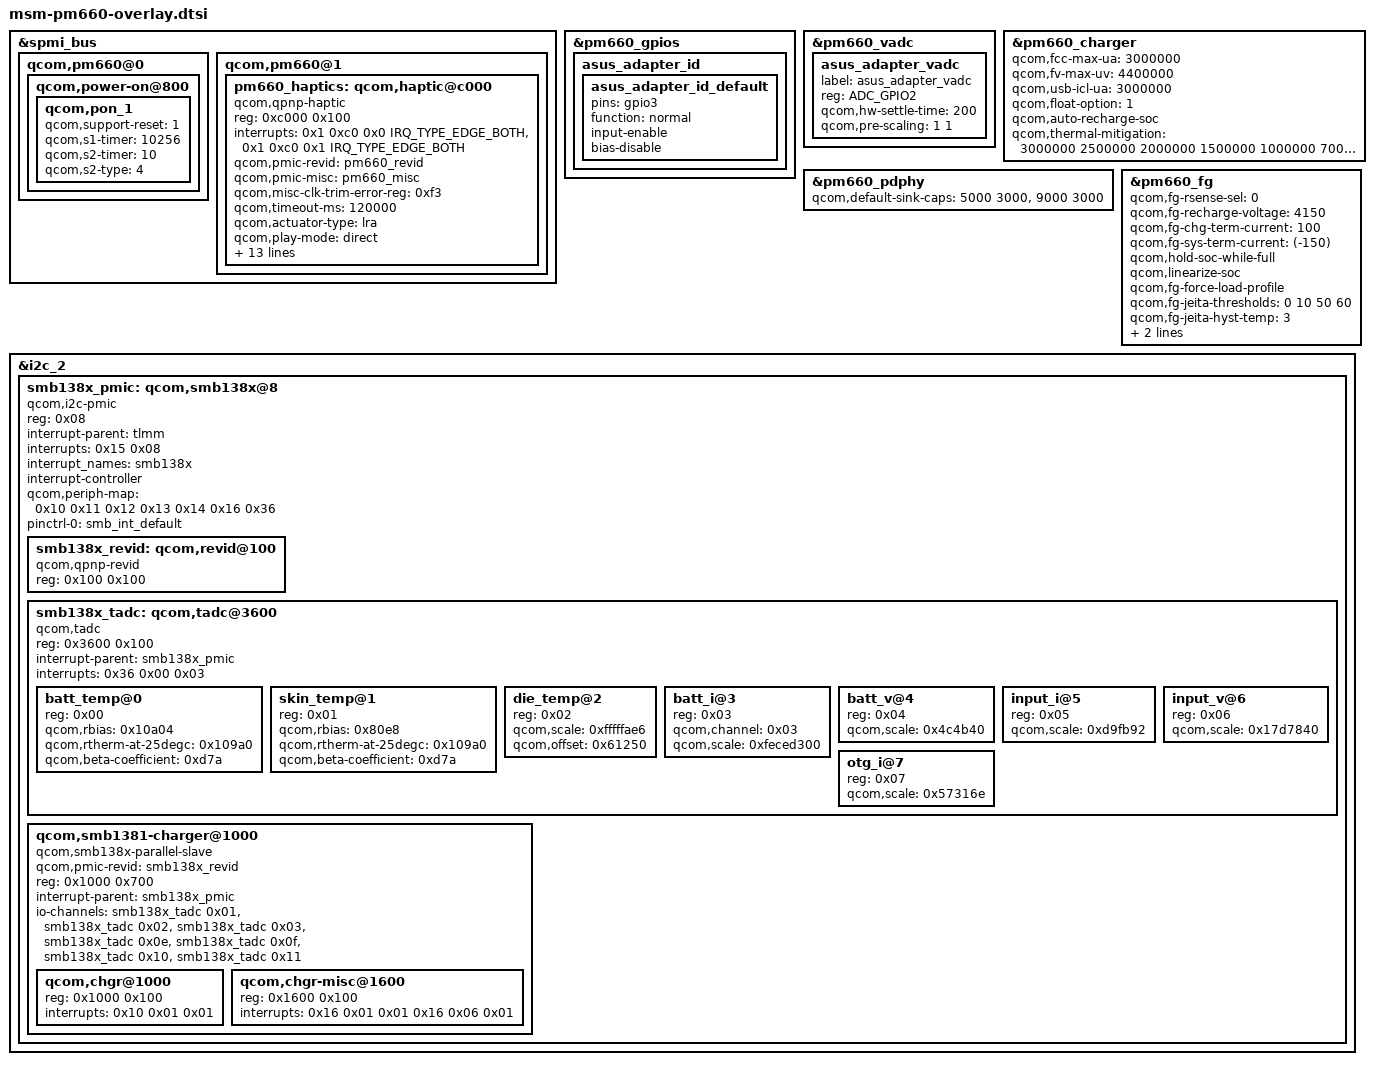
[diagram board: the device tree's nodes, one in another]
/* SPDX-License-Identifier: GPL-2.0 */

&spmi_bus {
	qcom,pm660@0 {
		qcom,power-on@800 {
			qcom,pon_1 {
				qcom,support-reset = <1>;
				qcom,s1-timer = <10256>;
				qcom,s2-timer = <10>;
				qcom,s2-type = <4>;
			};
		};
	};
};

&pm660_gpios {
	asus_adapter_id {
		asus_adapter_id_default: asus_adapter_id_default {
			pins = "gpio3";
			function = "normal";
			/* Input No pull */
			input-enable;
			bias-disable;
		};
	};
};

&pm660_vadc {
	asus_adapter_vadc {
		label = "asus_adapter_vadc";
		reg = <ADC_GPIO2>;
		qcom,hw-settle-time = <200>;
		qcom,pre-scaling = <1 1>;
	};
};

&pm660_charger {
	/* values aligned with stock ZUI dtb_58 (L78011 QPST firmware) */
	qcom,fcc-max-ua = <3000000>;
	qcom,fv-max-uv = <4400000>;
	qcom,usb-icl-ua = <3000000>;
	qcom,float-option = <1>;
	qcom,auto-recharge-soc;
	qcom,thermal-mitigation
			= <3000000 2500000 2000000 1500000
				1000000 700000>;
};

&pm660_pdphy {
	qcom,default-sink-caps = <5000 3000>, /* 5V @ 3A */
				 <9000 3000>; /* 9V @ 3A (stock ZUI dtb_58) */
};

&pm660_fg {
	qcom,fg-rsense-sel = <0>;
	qcom,fg-recharge-voltage = <4150>;  //WeiYu ++ for HW recharge
	qcom,fg-chg-term-current = <100>;
	qcom,fg-sys-term-current = <(-150)>;
	qcom,hold-soc-while-full;
	qcom,linearize-soc; //ASUS_BSP
	qcom,fg-force-load-profile;
	qcom,fg-jeita-thresholds = <0 10 50 60>;
	qcom,fg-jeita-hyst-temp = <3>;
	/* stock ZUI: auto recharge below 98% SOC */
	qcom,fg-auto-recharge-soc;
	qcom,fg-recharge-soc-thr = <98>;
};

&spmi_bus {
	qcom,pm660@1 {
		/delete-node/ qcom,haptics@c000;
		pm660_haptics: qcom,haptic@c000 {
			compatible = "qcom,qpnp-haptic";
			reg = <0xc000 0x100>;
			interrupts = <0x1 0xc0 0x0 IRQ_TYPE_EDGE_BOTH>,
				     <0x1 0xc0 0x1 IRQ_TYPE_EDGE_BOTH>;
			interrupt-names = "sc-irq", "play-irq";
			qcom,pmic-revid = <&pm660_revid>;
			qcom,pmic-misc = <&pm660_misc>;
			qcom,misc-clk-trim-error-reg = <0xf3>;
			qcom,timeout-ms = <120000>;
			qcom,actuator-type = "lra";
			qcom,play-mode = "direct";
			qcom,vmax-mv = <2784>;
			qcom,ilim-ma = <800>;
			qcom,wave-shape = "sine";
			qcom,wave-play-rate-us = <4255>; //235Hz (0x30D40 / 0x353)
			qcom,int-pwm-freq-khz = <505>;
			qcom,sc-deb-cycles = <8>;
			qcom,en-brake;
			qcom,brake-pattern = [02 02 02 02];
			qcom,lra-high-z = "opt0";
			qcom,lra-auto-res-mode = "none";
			qcom,lra-calibrate-at-eop = <0>;
			qcom,time-required-to-generate-back-emf-us = <5000>;
		};
	};
};

&spmi_bus {
	qcom,pm660@1 {
		/delete-node/ qcom,haptics@c000;
		pm660_haptics: qcom,haptic@c000 {
			compatible = "qcom,qpnp-haptic";
			reg = <0xc000 0x100>;
			interrupts = <0x1 0xc0 0x0 IRQ_TYPE_EDGE_BOTH>,
				     <0x1 0xc0 0x1 IRQ_TYPE_EDGE_BOTH>;
			interrupt-names = "sc-irq", "play-irq";
			qcom,pmic-revid = <&pm660_revid>;
			qcom,pmic-misc = <&pm660_misc>;
			qcom,misc-clk-trim-error-reg = <0xf3>;
			qcom,timeout-ms = <120000>;
			qcom,actuator-type = "lra";
			qcom,play-mode = "direct";
			qcom,vmax-mv = <2784>;
			qcom,ilim-ma = <800>;
			qcom,wave-shape = "sine";
			qcom,wave-play-rate-us = <4255>; //235Hz (0x30D40 / 0x353)
			qcom,int-pwm-freq-khz = <505>;
			qcom,sc-deb-cycles = <8>;
			qcom,en-brake;
			qcom,brake-pattern = [02 02 02 02];
			qcom,lra-high-z = "opt0";
			qcom,lra-auto-res-mode = "none";
			qcom,lra-calibrate-at-eop = <0>;
//			qcom,correct-lra-drive-freq;
//			qcom,perform-lra-auto-resonance-search;
//			qcom,lra-hw-auto-resonance;
			qcom,time-required-to-generate-back-emf-us = <5000>;
		};
	};
};

/* Stock ZUI parallel charger: smb138x@8 on i2c2 (replaces X00QD-inherited smb1351).
 * Ported byte-for-byte from stock dtb_58 (L78011 QPST), phandles converted to labels. */
&i2c_2 {
	/delete-node/ smb1351-charger@1d;

	smb138x_pmic: qcom,smb138x@8 {
		compatible = "qcom,i2c-pmic";
		reg = <0x08>;
		#address-cells = <1>;
		#size-cells = <1>;
		interrupt-parent = <&tlmm>;
		interrupts = <0x15 0x08>;	/* TLMM gpio21, level-low */
		interrupt_names = "smb138x";
		interrupt-controller;
		#interrupt-cells = <3>;
		qcom,periph-map = <0x10 0x11 0x12 0x13 0x14 0x16 0x36>;
		pinctrl-names = "default";
		pinctrl-0 = <&smb_int_default>;

		smb138x_revid: qcom,revid@100 {
			compatible = "qcom,qpnp-revid";
			reg = <0x100 0x100>;
		};

		smb138x_tadc: qcom,tadc@3600 {
			compatible = "qcom,tadc";
			reg = <0x3600 0x100>;
			#address-cells = <1>;
			#size-cells = <0>;
			#io-channel-cells = <1>;
			interrupt-parent = <&smb138x_pmic>;
			interrupts = <0x36 0x00 0x03>;
			interrupt-names = "eoc";

			batt_temp@0 {
				reg = <0x00>;
				qcom,rbias = <0x10a04>;
				qcom,rtherm-at-25degc = <0x109a0>;
				qcom,beta-coefficient = <0xd7a>;
			};

			skin_temp@1 {
				reg = <0x01>;
				qcom,rbias = <0x80e8>;
				qcom,rtherm-at-25degc = <0x109a0>;
				qcom,beta-coefficient = <0xd7a>;
			};

			die_temp@2 {
				reg = <0x02>;
				qcom,scale = <0xfffffae6>;
				qcom,offset = <0x61250>;
			};

			batt_i@3 {
				reg = <0x03>;
				qcom,channel = <0x03>;
				qcom,scale = <0xfeced300>;
			};

			batt_v@4 {
				reg = <0x04>;
				qcom,scale = <0x4c4b40>;
			};

			input_i@5 {
				reg = <0x05>;
				qcom,scale = <0xd9fb92>;
			};

			input_v@6 {
				reg = <0x06>;
				qcom,scale = <0x17d7840>;
			};

			otg_i@7 {
				reg = <0x07>;
				qcom,scale = <0x57316e>;
			};
		};

		qcom,smb1381-charger@1000 {
			compatible = "qcom,smb138x-parallel-slave";
			qcom,pmic-revid = <&smb138x_revid>;
			reg = <0x1000 0x700>;
			#address-cells = <1>;
			#size-cells = <1>;
			interrupt-parent = <&smb138x_pmic>;
			io-channels = <&smb138x_tadc 0x01 &smb138x_tadc 0x02
					&smb138x_tadc 0x03 &smb138x_tadc 0x0e
					&smb138x_tadc 0x0f &smb138x_tadc 0x10
					&smb138x_tadc 0x11>;
			io-channel-names = "connector_temp",
					"charger_temp",
					"batt_i",
					"connector_temp_thr1",
					"connector_temp_thr2",
					"connector_temp_thr3",
					"charger_temp_max";

			qcom,chgr@1000 {
				reg = <0x1000 0x100>;
				interrupts = <0x10 0x01 0x01>;
				interrupt-names = "chg-state-change";
			};

			qcom,chgr-misc@1600 {
				reg = <0x1600 0x100>;
				interrupts = <0x16 0x01 0x01 0x16 0x06 0x01>;
				interrupt-names = "wdog-bark",
						"temperature-change";
			};
		};
	};
};
